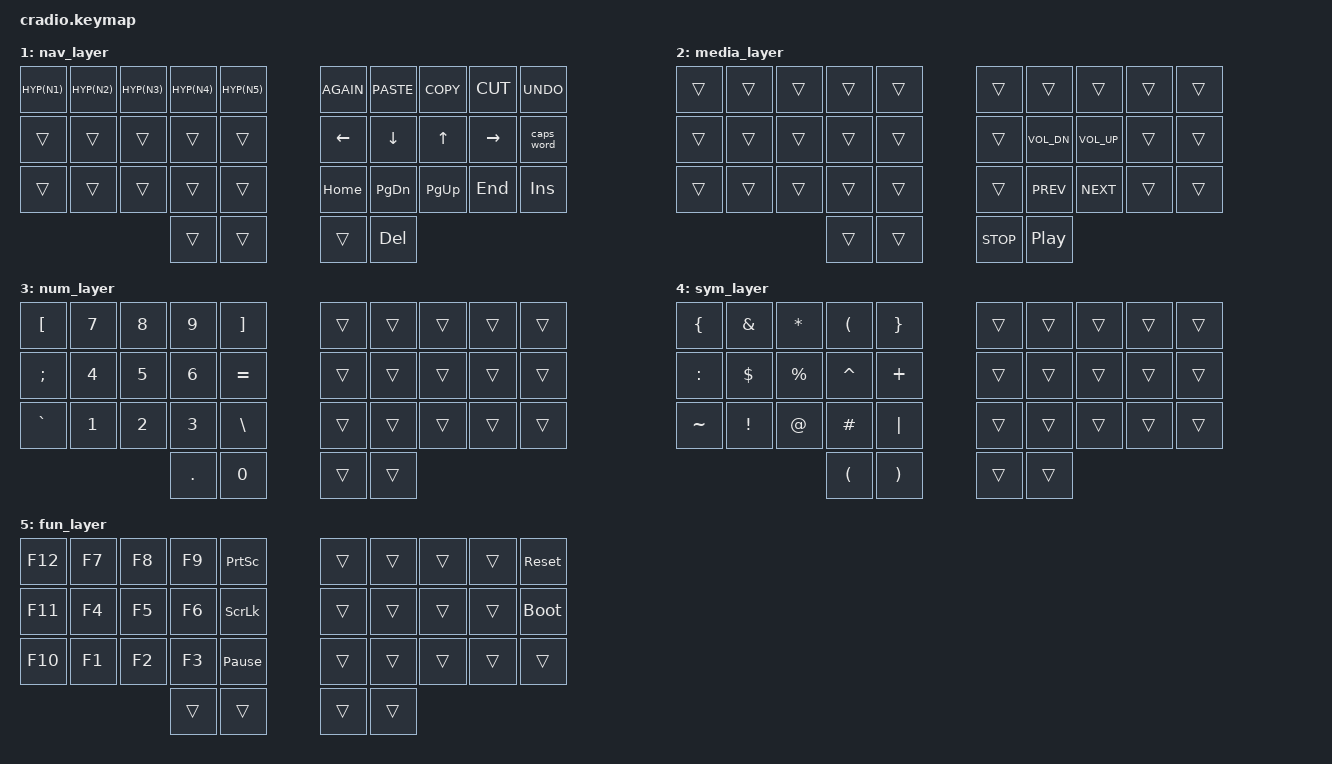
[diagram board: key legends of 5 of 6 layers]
// Copyright (c) 2022 The ZMK Contributors
// SPDX-License-Identifier: MIT

#include <behaviors.dtsi>
#include <dt-bindings/zmk/keys.h>
#include <dt-bindings/zmk/bt.h>

#define BASE 0
#define NAV 1
#define MEDIA 2
#define NUM 3
#define SYM 4
#define FUN 5

// Home row mods macro
#define HRML(k1,k2,k3,k4) &ht LSHFT k1  &ht LALT k2  &ht LCTRL k3  &ht LGUI k4
#define HRMR(k1,k2,k3,k4) &ht RGUI k1  &ht RCTRL k2  &ht RALT k3  &ht RSHFT k4
#define HYP(key) &kp LC(LA(LS(LG(key))))

/ {
    combos {
        compatible = "zmk,combos";
        
        combo_esc_left {
            timeout-ms = <50>;
            key-positions = <0 1>; 
            bindings = <&kp ESC>;
        };
    };
    
    behaviors {
        ht: hold_tap {
            compatible = "zmk,behavior-hold-tap";
            #binding-cells = <2>;
            flavor = "tap-preferred";
            tapping-term-ms = <220>;
            quick-tap-ms = <150>;
            require-prior-idle-ms = <100>;
            bindings = <&kp>, <&kp>;
        };
    };

    conditional_layers {
        compatible = "zmk,conditional-layers";
        tri_layer {
            if-layers = <1 4>;
            then-layer = <5>;
        };
    };

    keymap {
        compatible = "zmk,keymap";

        default_layer {
            bindings = <
        //╭──────────┬──────────┬──────────┬──────────┬──────────╮   ╭──────────┬──────────┬──────────┬──────────┬──────────╮
        //│  Q       │  W       │  F       │  P       │  G       │   │  J       │  L       │  U       │  Y       │  ;       │
            &kp Q      &kp W      &kp F      &kp P      &kp G          &kp J      &kp L      &kp U      &kp Y      &kp SQT
        //├──────────┼──────────┼──────────┼──────────┼──────────┤   ├──────────┼──────────┼──────────┼──────────┼──────────┤
        //│  A       │  R       │  S       │  T       │  D       │   │  H       │  N       │  E       │  I       │  O       │
            HRML(A,        R,         S,         T)     &kp D          &kp H      HRMR(N,        E,         I,         O)
        //├──────────┼──────────┼──────────┼──────────┼──────────┤   ├──────────┼──────────┼──────────┼──────────┼──────────┤
        //│  Z       │  X       │  C       │  V       │  B       │   │  K       │  M       │ , <      │ . >      │ / ?      │
            &kp Z      &kp X      &kp C      &kp V      &kp B          &kp K      &kp M      &kp COMMA  &kp DOT    &kp FSLH
        //╰──────────┴──────────┴──────────┼──────────┼──────────┤   ├──────────┼──────────┼──────────┴──────────┴──────────╯
                                         &lt MEDIA SPACE &lt NAV TAB &lt SYM RET &lt NUM BSPC
        //                                 ╰──────────┴──────────╯   ╰──────────┴──────────╯
            >;
        };

        // LAYER 1: NAV (Left Inner Thumb)
        nav_layer {
            bindings = <
            HYP(N1)    HYP(N2)    HYP(N3)    HYP(N4)    HYP(N5)         &kp K_AGAIN &kp K_PASTE &kp K_COPY &kp K_CUT  &kp K_UNDO
            &trans     &trans     &trans     &trans     &trans         &kp LEFT    &kp DOWN    &kp UP     &kp RIGHT  &caps_word
            &trans     &trans     &trans     &trans     &trans         &kp HOME    &kp PG_DN   &kp PG_UP  &kp END    &kp INS
                                             &trans     &trans         &trans      &kp DEL
            >;
        };

        // LAYER 2: MEDIA (Left Outer Thumb)
        media_layer {
            bindings = <
            &trans     &trans     &trans     &trans     &trans         &trans     &trans       &trans       &trans     &trans
            &trans     &trans     &trans     &trans     &trans         &trans     &kp C_VOL_DN &kp C_VOL_UP &trans     &trans
            &trans     &trans     &trans     &trans     &trans         &trans     &kp C_PREV   &kp C_NEXT   &trans     &trans
                                             &trans     &trans         &kp C_STOP &kp C_PP
            >;
        };

        // LAYER 3: NUM (Right Outer Thumb)
        num_layer {
            bindings = <
            &kp LBKT   &kp N7     &kp N8     &kp N9     &kp RBKT       &trans     &trans     &trans     &trans     &trans
            &kp SEMI   &kp N4     &kp N5     &kp N6     &kp EQUAL      &trans     &trans     &trans     &trans     &trans
            &kp GRAVE  &kp N1     &kp N2     &kp N3     &kp BSLH       &trans     &trans     &trans     &trans     &trans
                                             &kp DOT    &kp N0         &trans     &trans
            >;
        };

        // LAYER 4: SYM (Right Inner Thumb)
        sym_layer {
            bindings = <
            &kp LBRC   &kp AMPS   &kp STAR   &kp LPAR   &kp RBRC       &trans     &trans     &trans     &trans     &trans
            &kp COLON  &kp DLLR   &kp PRCNT  &kp CARET  &kp PLUS       &trans     &trans     &trans     &trans     &trans
            &kp TILDE  &kp EXCL   &kp AT     &kp HASH   &kp PIPE       &trans     &trans     &trans     &trans     &trans
                                             &kp LPAR   &kp RPAR       &trans     &trans
            >;
        };

        // LAYER 5: FUN (Nav + Sym)
        fun_layer {
            bindings = <
            &kp F12    &kp F7     &kp F8     &kp F9   &kp PSCRN        &trans     &trans     &trans     &trans     &sys_reset
            &kp F11    &kp F4     &kp F5     &kp F6   &kp SLCK         &trans     &trans     &trans     &trans     &bootloader
            &kp F10    &kp F1     &kp F2     &kp F3   &kp PAUSE_BREAK  &trans     &trans     &trans     &trans     &trans
                                             &trans   &trans           &trans     &trans
            >;
        };
    };
};
